# cm7 register map
Registers are 32-bit, read-write, reset 0x0 unless marked. A register's access mark holds for its fields unless they carry their own. Offsets are from the block's base; lines under a group give offsets from that group; [hi:lo] are bit positions; {n}, {i} and the like mark numbered series; 'fields as' and 'values as' point back to an identical list; <NAME> marks a mode.

## Memory map
0xE0001000 DWT size 0xFB8 — Data Watchpoint Trace
0xE000E000 SCB size 0x8 — System control block
0xE000E010 SysTick size 0x10 — 24Bit System Tick Timer for use in RTOS
0xE000E100 NVIC size 0x350
0xE000ED00 Debug size 0x100
0xE000ED78 PF size 0x10 — Processor Features
0xE000ED88 FPU size 0x1B8 — Floating Point Unit
0xE000ED90 MPU size 0x30 — Memory Protection Unit
0xE000EF50 Cache size 0x2C — Cache maintenance operations

## NVIC
Base 0xE000E100
{0x0+4i} NVIC_ISER[{i}] (i=0..7) ro reset not defined — Interrupt Set-Enable Registers
{0x80+4i} NVIC_ICER[{i}] (i=0..7) ro reset not defined — Interrupt Clear-Enable Registers
{0x100+4i} NVIC_ISPR[{i}] (i=0..7) ro reset not defined — Interrupt Set-Pending Registers
{0x180+4i} NVIC_ICPR[{i}] (i=0..7) ro reset not defined — Interrupt Clear-Pending Registers
{0x200+4i} NVIC_IABR[{i}] (i=0..7) ro reset not defined — Interrupt Active Bit Register
{0x300+4i} NVIC_IPR[{i}] (i=0..59) ro reset not defined — Interrupt Priority Register
0xE00 STIR wo reset not defined — Software Trigger Interrupt Register
  [8:0] INTID — Interrupt ID of the interrupt to trigger, in the range 0-239.

## SysTick — 24Bit System Tick Timer for use in RTOS
Base 0xE000E010; register names take the prefix SYST_
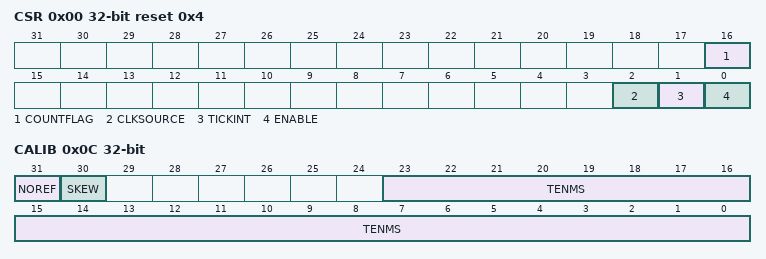
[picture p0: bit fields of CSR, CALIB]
0x00 CSR reset 0x4 — SysTick Control and Status Register
  [16] COUNTFLAG — SysTick counted to zero
  [2] CLKSOURCE — Source to count from
    0=External_Clk (External Clock); 1=CPU_Clk (CPU Clock)
  [1] TICKINT — Generate Tick Interrupt
    0=Disable (Counting down to zero asserts the SysTick exception request); 1=Enable (Counting down to zero does not assert the SysTick exception request)
  [0] ENABLE — Enable SysTick Timer
    0=Disable (counter disabled); 1=Enable (counter enabled)
0x04 RVR — SysTick Reload Value Register
  [23:0] RELOAD — Value to auto reload SysTick after reaching zero
0x08 CVR — SysTick Current Value Register
  [23:0] CURRENT — Current value
0x0C CALIB ro — SysTick Calibration Value Register
  [31] NOREF
    0=Ref_Clk_Available; 1=Ref_Clk_Unavailable (Ref Clk not available)
  [30] SKEW — Clock Skew
    0=Exact (10ms calibration value is exact); 1=Inexact (10ms calibration value is inexact, because of the clock frequency)
  [23:0] TENMS — Reload value to use for 10ms timing

## FPU — Floating Point Unit
Base 0xE000ED88
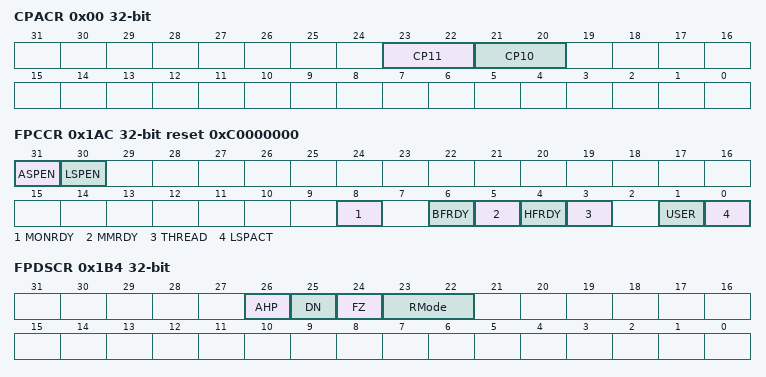
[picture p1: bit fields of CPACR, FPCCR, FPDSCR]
0x00 CPACR — Coprocessor Access Control Register
  [23:22] CP11 — Access privileges for coprocessor 11.
    0=Access_Denied (Any attempted access generates a NOCP UsageFault.); 1=Privileged access only. An unprivileged addess generates a NOCP UsageFault.; 3=Full_Access
  [21:20] CP10 — Access privileges for coprocessor 10.
    values as CP11
0x1AC FPCCR access per field reset 0xC0000000 — Floating-Point Context Control Register
  [31] ASPEN rw — Enables CONTROL.FPCA setting on execution of a floating point instruction. This results in automatic hardware state preservation and restoration, for floating-point context, on exception entry and exit.
  [30] LSPEN rw — Enables automatic lazy state preservation for floating-point context.
  [8] MONRDY ro — If set, DebugMonitor is enabled and priority permitted setting the DebugMonitor handler to the pending state when the floating-point stack frame was allocated.
  [6] BFRDY ro — If set, BusFault is enabled and priority permitted setting the BusFault handler to the pending state when the floating-point stack frame was allocated.
  [5] MMRDY ro — If set, MemManage is enabled and priority permitted setting the MemManage handler to the pending state when the floating-point stack frame was allocated.
  [4] HFRDY ro — If set, priority permitted setting the HardFault handler to the pending state when the floating-point stack frame was allocated.
  [3] THREAD ro — If set, the mode was Thread Mode when the floating-point stack frame was allocated.
  [1] USER ro — If set, privilege level was user when the floating-point stack frame was allocated.
  [0] LSPACT rw — Lazy state preservation activation.
0x1B0 FPCAR — Floating-Point Context Address Register
  [31:3] ADDRESS — The FPCAR register holds the location of the unpopulated floating-point register space allocated on an exception stack frame.
0x1B4 FPDSCR — Floating-Point Default Status Control Register
  [26] AHP — Default value for FPSCR.AHP.
  [25] DN — Default value for FPSCR.DN.
  [24] FZ — Default value for FPSCR.FZ.
  [23:22] RMode — Default value for FPSCR.RMode.

## Notices in the file
Copyright (C) 2016 AdaCore
